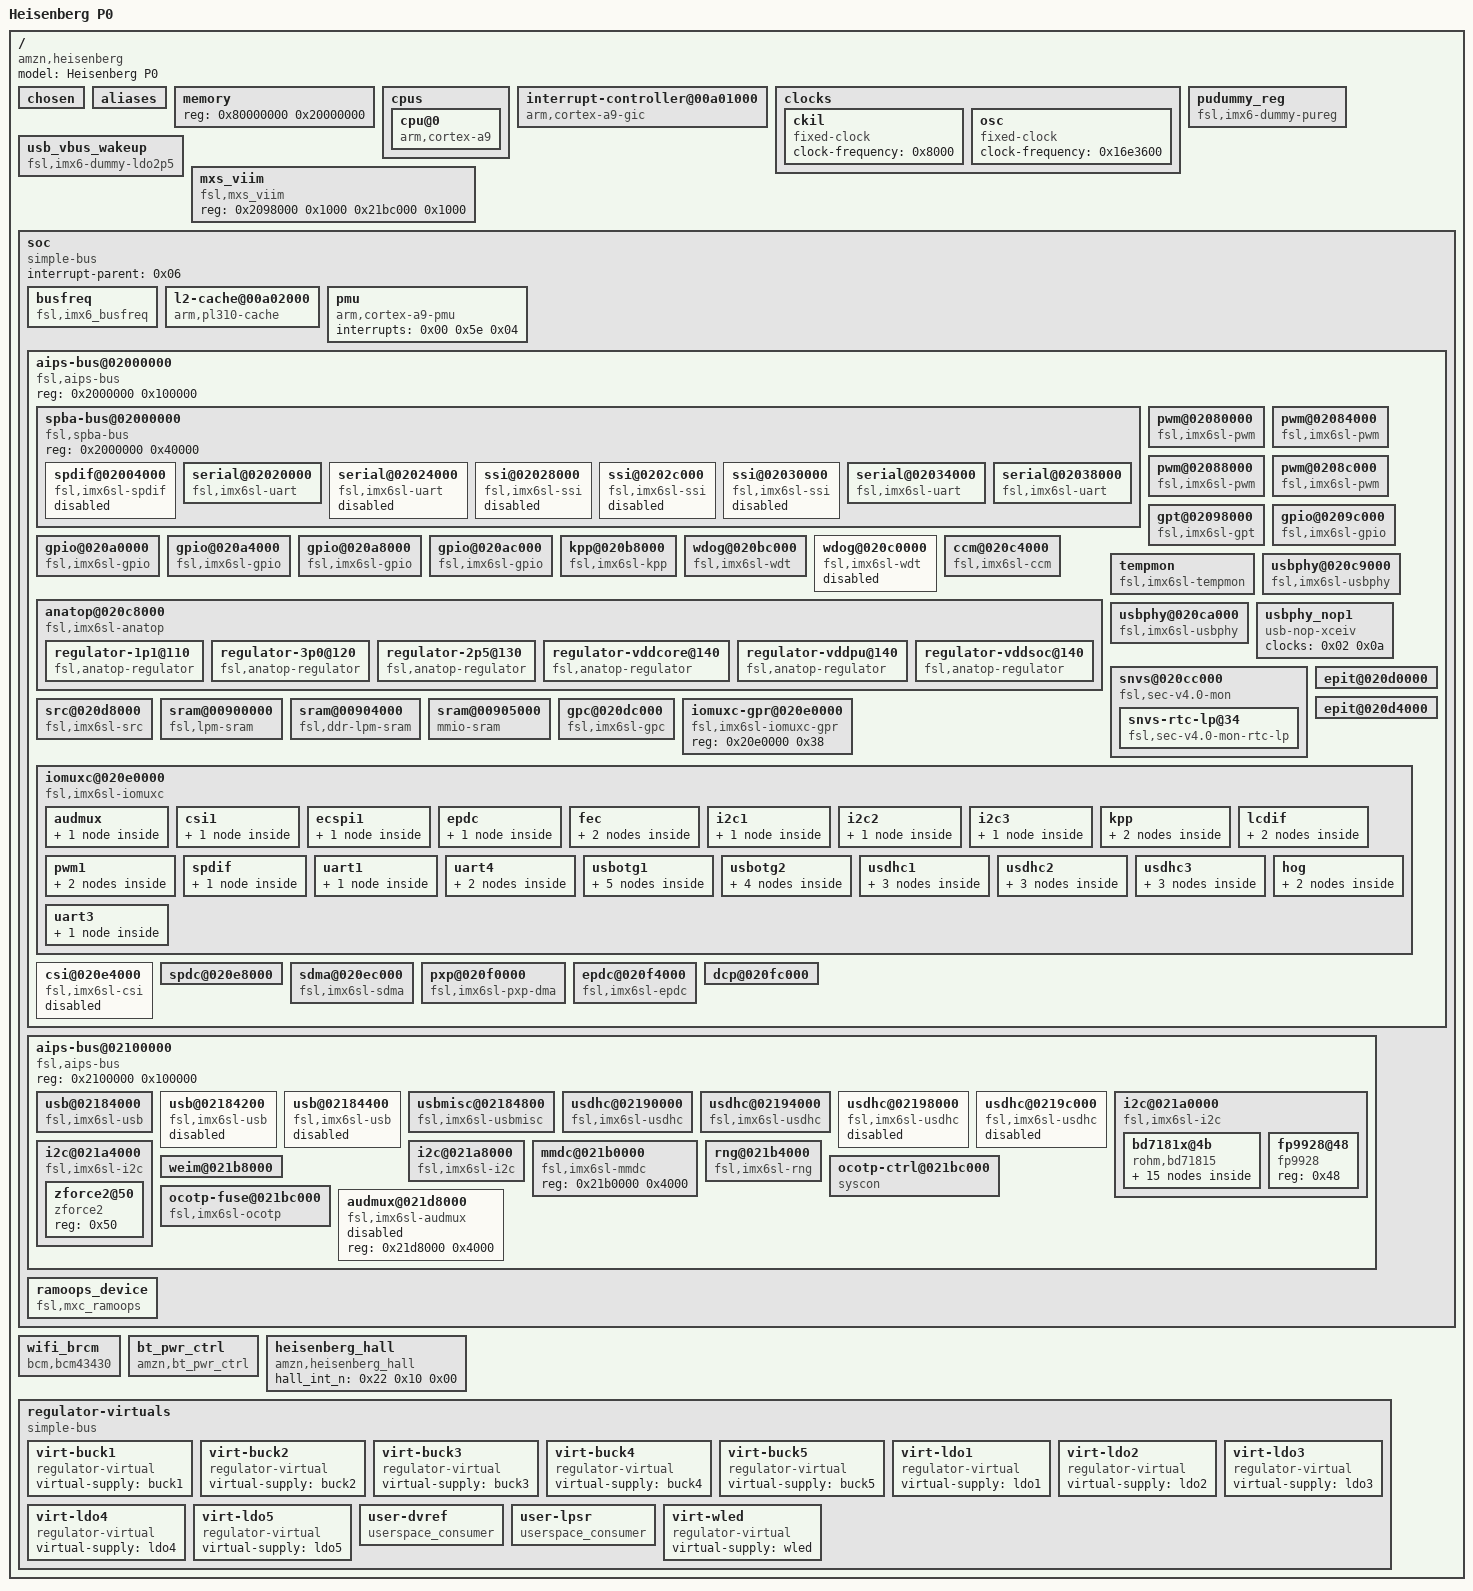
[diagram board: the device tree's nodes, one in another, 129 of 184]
/dts-v1/;

/ {
	#address-cells = <0x01>;
	#size-cells = <0x01>;
	model = "Heisenberg P0";
	compatible = "amzn,heisenberg\0fsl,imx6sl";

	chosen {
	};

	aliases {
		csi0 = "/soc/aips-bus@02000000/csi@020e4000";
		mmc1 = "/soc/aips-bus@02100000/usdhc@02190000";
		mmc0 = "/soc/aips-bus@02100000/usdhc@02194000";
		mmc2 = "/soc/aips-bus@02100000/usdhc@02198000";
		mmc3 = "/soc/aips-bus@02100000/usdhc@0219c000";
		serial0 = "/soc/aips-bus@02000000/spba-bus@02000000/serial@02020000";
		serial1 = "/soc/aips-bus@02000000/spba-bus@02000000/serial@02024000";
		serial2 = "/soc/aips-bus@02000000/spba-bus@02000000/serial@02034000";
		serial3 = "/soc/aips-bus@02000000/spba-bus@02000000/serial@02038000";
		gpio0 = "/soc/aips-bus@02000000/gpio@0209c000";
		gpio1 = "/soc/aips-bus@02000000/gpio@020a0000";
		gpio2 = "/soc/aips-bus@02000000/gpio@020a4000";
		gpio3 = "/soc/aips-bus@02000000/gpio@020a8000";
		gpio4 = "/soc/aips-bus@02000000/gpio@020ac000";
		usbphy0 = "/soc/aips-bus@02000000/usbphy@020c9000";
		usbphy1 = "/soc/aips-bus@02000000/usbphy@020ca000";
	};

	memory {
		device_type = "memory";
		reg = <0x80000000 0x20000000>;
	};

	cpus {
		#address-cells = <0x01>;
		#size-cells = <0x00>;

		cpu@0 {
			compatible = "arm,cortex-a9";
			device_type = "cpu";
			reg = <0x00>;
			next-level-cache = <0x01>;
			operating-points = <0xf32a0 0x137478 0x60ae0 0xee098>;
			fsl,soc-operating-points = <0xf32a0 0x12b128 0x60ae0 0x11edd8>;
			clock-latency = <0xee6c>;
			clocks = <0x02 0x5f 0x02 0x14 0x02 0x1d 0x02 0x1e 0x02 0x03>;
			clock-names = "arm\0pll2_pfd2_396m\0step\0pll1_sw\0pll1_sys";
			arm-supply = <0x03>;
			pu-supply = <0x04>;
			soc-supply = <0x05>;
		};
	};

	interrupt-controller@00a01000 {
		compatible = "arm,cortex-a9-gic";
		#interrupt-cells = <0x03>;
		#address-cells = <0x01>;
		#size-cells = <0x01>;
		interrupt-controller;
		reg = <0xa01000 0x1000 0xa00100 0x100>;
		linux,phandle = <0x06>;
		phandle = <0x06>;
	};

	clocks {
		#address-cells = <0x01>;
		#size-cells = <0x00>;

		ckil {
			compatible = "fixed-clock";
			clock-frequency = <0x8000>;
		};

		osc {
			compatible = "fixed-clock";
			clock-frequency = <0x16e3600>;
		};
	};

	pudummy_reg {
		compatible = "fsl,imx6-dummy-pureg";
		linux,phandle = <0x04>;
		phandle = <0x04>;
	};

	usb_vbus_wakeup {
		compatible = "fsl,imx6-dummy-ldo2p5";
		linux,phandle = <0x1a>;
		phandle = <0x1a>;
	};

	mxs_viim {
		compatible = "fsl,mxs_viim";
		reg = <0x2098000 0x1000 0x21bc000 0x1000>;
	};

	soc {
		#address-cells = <0x01>;
		#size-cells = <0x01>;
		compatible = "simple-bus";
		interrupt-parent = <0x06>;
		ranges;

		busfreq {
			compatible = "fsl,imx6_busfreq";
			clocks = <0x02 0x04 0x02 0x14 0x02 0x19 0x02 0x5f 0x02 0x05 0x02 0x3a 0x02 0x22 0x02 0x3d 0x02 0x24 0x02 0x02 0x02 0x03 0x02 0x3b 0x02 0x5d 0x02 0x74 0x02 0x1e 0x02 0x21 0x02 0x23 0x02 0x3e 0x02 0x1d>;
			clock-names = "pll2_bus\0pll2_pfd2_396m\0pll2_198m\0arm\0pll3_usb_otg\0periph\0periph_pre\0periph_clk2\0periph_clk2_sel\0osc\0pll1_sys\0periph2\0ahb\0ocram\0pll1_sw\0periph2_pre\0periph2_clk2_sel\0periph2_clk2\0step";
			fsl,max_ddr_freq = <0x17d78400>;
		};

		l2-cache@00a02000 {
			compatible = "arm,pl310-cache";
			reg = <0xa02000 0x1000>;
			interrupts = <0x00 0x5c 0x04>;
			cache-unified;
			cache-level = <0x02>;
			arm,tag-latency = <0x04 0x02 0x03>;
			arm,data-latency = <0x04 0x02 0x03>;
			linux,phandle = <0x01>;
			phandle = <0x01>;
		};

		pmu {
			compatible = "arm,cortex-a9-pmu";
			interrupts = <0x00 0x5e 0x04>;
		};

		aips-bus@02000000 {
			compatible = "fsl,aips-bus\0simple-bus";
			#address-cells = <0x01>;
			#size-cells = <0x01>;
			reg = <0x2000000 0x100000>;
			ranges;

			spba-bus@02000000 {
				compatible = "fsl,spba-bus\0simple-bus";
				#address-cells = <0x01>;
				#size-cells = <0x01>;
				reg = <0x2000000 0x40000>;
				ranges;

				spdif@02004000 {
					compatible = "fsl,imx6sl-spdif\0fsl,imx35-spdif";
					reg = <0x2004000 0x4000>;
					interrupts = <0x00 0x34 0x04>;
					dmas = <0x07 0x0e 0x12 0x00 0x07 0x0f 0x12 0x00>;
					dma-names = "rx\0tx";
					clocks = <0x02 0x7a 0x02 0x02 0x02 0x7a 0x02 0x00 0x02 0x00 0x02 0x00 0x02 0x3f 0x02 0x00 0x02 0x00 0x02 0x88>;
					clock-names = "core\0rxtx0\0rxtx1\0rxtx2\0rxtx3\0rxtx4\0rxtx5\0rxtx6\0rxtx7\0dma";
					status = "disabled";
				};

				serial@02020000 {
					compatible = "fsl,imx6sl-uart\0fsl,imx21-uart";
					reg = <0x2020000 0x4000>;
					interrupts = <0x00 0x1a 0x04>;
					clocks = <0x02 0x7e 0x02 0x7f>;
					clock-names = "ipg\0per";
					dmas = <0x07 0x19 0x04 0x00 0x07 0x1a 0x04 0x00>;
					dma-names = "rx\0tx";
					status = "okay";
					pinctrl-names = "default";
					pinctrl-0 = <0x08>;
				};

				serial@02024000 {
					compatible = "fsl,imx6sl-uart\0fsl,imx21-uart";
					reg = <0x2024000 0x4000>;
					interrupts = <0x00 0x1b 0x04>;
					clocks = <0x02 0x7e 0x02 0x7f>;
					clock-names = "ipg\0per";
					dmas = <0x07 0x1b 0x04 0x00 0x07 0x1c 0x04 0x00>;
					dma-names = "rx\0tx";
					status = "disabled";
				};

				ssi@02028000 {
					compatible = "fsl,imx6sl-ssi\0fsl,imx21-ssi";
					reg = <0x2028000 0x4000>;
					interrupts = <0x00 0x2e 0x04>;
					clocks = <0x02 0x7b 0x02 0x7b>;
					clock-names = "ipg\0baud";
					dmas = <0x07 0x25 0x01 0x00 0x07 0x26 0x01 0x00>;
					dma-names = "rx\0tx";
					status = "disabled";
				};

				ssi@0202c000 {
					compatible = "fsl,imx6sl-ssi\0fsl,imx21-ssi";
					reg = <0x202c000 0x4000>;
					interrupts = <0x00 0x2f 0x04>;
					clocks = <0x02 0x7c 0x02 0x7c>;
					clock-names = "ipg\0baud";
					dmas = <0x07 0x29 0x01 0x00 0x07 0x2a 0x01 0x00>;
					dma-names = "rx\0tx";
					status = "disabled";
				};

				ssi@02030000 {
					compatible = "fsl,imx6sl-ssi\0fsl,imx21-ssi";
					reg = <0x2030000 0x4000>;
					interrupts = <0x00 0x30 0x04>;
					clocks = <0x02 0x7d 0x02 0x7d>;
					clock-names = "ipg\0baud";
					dmas = <0x07 0x2d 0x01 0x00 0x07 0x2e 0x01 0x00>;
					dma-names = "rx\0tx";
					status = "disabled";
				};

				serial@02034000 {
					compatible = "fsl,imx6sl-uart\0fsl,imx21-uart";
					reg = <0x2034000 0x4000>;
					interrupts = <0x00 0x1c 0x04>;
					clocks = <0x02 0x7e 0x02 0x7f>;
					clock-names = "ipg\0per";
					dmas = <0x07 0x1d 0x04 0x00 0x07 0x1e 0x04 0x00>;
					dma-names = "rx\0tx";
					status = "okay";
					pinctrl-names = "default";
					pinctrl-0 = <0x09>;
					fsl,uart-has-rtscts;
				};

				serial@02038000 {
					compatible = "fsl,imx6sl-uart\0fsl,imx21-uart";
					reg = <0x2038000 0x4000>;
					interrupts = <0x00 0x1d 0x04>;
					clocks = <0x02 0x7e 0x02 0x7f>;
					clock-names = "ipg\0per";
					dmas = <0x07 0x1f 0x04 0x00 0x07 0x20 0x04 0x00>;
					dma-names = "rx\0tx";
					status = "okay";
					pinctrl-names = "default";
					pinctrl-0 = <0x0a>;
				};
			};

			pwm@02080000 {
				#pwm-cells = <0x02>;
				compatible = "fsl,imx6sl-pwm\0fsl,imx27-pwm";
				reg = <0x2080000 0x4000>;
				interrupts = <0x00 0x53 0x04>;
				clocks = <0x02 0x75 0x02 0x75>;
				clock-names = "ipg\0per";
			};

			pwm@02084000 {
				#pwm-cells = <0x02>;
				compatible = "fsl,imx6sl-pwm\0fsl,imx27-pwm";
				reg = <0x2084000 0x4000>;
				interrupts = <0x00 0x54 0x04>;
				clocks = <0x02 0x76 0x02 0x76>;
				clock-names = "ipg\0per";
			};

			pwm@02088000 {
				#pwm-cells = <0x02>;
				compatible = "fsl,imx6sl-pwm\0fsl,imx27-pwm";
				reg = <0x2088000 0x4000>;
				interrupts = <0x00 0x55 0x04>;
				clocks = <0x02 0x77 0x02 0x77>;
				clock-names = "ipg\0per";
			};

			pwm@0208c000 {
				#pwm-cells = <0x02>;
				compatible = "fsl,imx6sl-pwm\0fsl,imx27-pwm";
				reg = <0x208c000 0x4000>;
				interrupts = <0x00 0x56 0x04>;
				clocks = <0x02 0x78 0x02 0x78>;
				clock-names = "ipg\0per";
			};

			gpt@02098000 {
				compatible = "fsl,imx6sl-gpt";
				reg = <0x2098000 0x4000>;
				interrupts = <0x00 0x37 0x04>;
				clocks = <0x02 0x67 0x02 0x68>;
				clock-names = "ipg\0per";
			};

			gpio@0209c000 {
				compatible = "fsl,imx6sl-gpio\0fsl,imx35-gpio";
				reg = <0x209c000 0x4000>;
				interrupts = <0x00 0x42 0x04 0x00 0x43 0x04>;
				gpio-controller;
				#gpio-cells = <0x02>;
				interrupt-controller;
				#interrupt-cells = <0x02>;
			};

			gpio@020a0000 {
				compatible = "fsl,imx6sl-gpio\0fsl,imx35-gpio";
				reg = <0x20a0000 0x4000>;
				interrupts = <0x00 0x44 0x04 0x00 0x45 0x04>;
				gpio-controller;
				#gpio-cells = <0x02>;
				interrupt-controller;
				#interrupt-cells = <0x02>;
				linux,phandle = <0x25>;
				phandle = <0x25>;
			};

			gpio@020a4000 {
				compatible = "fsl,imx6sl-gpio\0fsl,imx35-gpio";
				reg = <0x20a4000 0x4000>;
				interrupts = <0x00 0x46 0x04 0x00 0x47 0x04>;
				gpio-controller;
				#gpio-cells = <0x02>;
				interrupt-controller;
				#interrupt-cells = <0x02>;
				linux,phandle = <0x26>;
				phandle = <0x26>;
			};

			gpio@020a8000 {
				compatible = "fsl,imx6sl-gpio\0fsl,imx35-gpio";
				reg = <0x20a8000 0x4000>;
				interrupts = <0x00 0x48 0x04 0x00 0x49 0x04>;
				gpio-controller;
				#gpio-cells = <0x02>;
				interrupt-controller;
				#interrupt-cells = <0x02>;
				linux,phandle = <0x22>;
				phandle = <0x22>;
			};

			gpio@020ac000 {
				compatible = "fsl,imx6sl-gpio\0fsl,imx35-gpio";
				reg = <0x20ac000 0x4000>;
				interrupts = <0x00 0x4a 0x04 0x00 0x4b 0x04>;
				gpio-controller;
				#gpio-cells = <0x02>;
				interrupt-controller;
				#interrupt-cells = <0x02>;
				linux,phandle = <0x27>;
				phandle = <0x27>;
			};

			kpp@020b8000 {
				compatible = "fsl,imx6sl-kpp\0fsl,imx21-kpp";
				reg = <0x20b8000 0x4000>;
				interrupts = <0x00 0x52 0x04>;
				clocks = <0x02 0x00>;
				pinctrl-names = "default";
				pinctrl-0 = <0x0b>;
				status = "okay";
			};

			wdog@020bc000 {
				compatible = "fsl,imx6sl-wdt\0fsl,imx21-wdt";
				reg = <0x20bc000 0x4000>;
				interrupts = <0x00 0x50 0x04>;
				clocks = <0x02 0x00>;
			};

			wdog@020c0000 {
				compatible = "fsl,imx6sl-wdt\0fsl,imx21-wdt";
				reg = <0x20c0000 0x4000>;
				interrupts = <0x00 0x51 0x04>;
				clocks = <0x02 0x00>;
				status = "disabled";
			};

			ccm@020c4000 {
				compatible = "fsl,imx6sl-ccm";
				reg = <0x20c4000 0x4000>;
				interrupts = <0x00 0x57 0x04 0x00 0x58 0x04>;
				#clock-cells = <0x01>;
				linux,phandle = <0x02>;
				phandle = <0x02>;
			};

			anatop@020c8000 {
				compatible = "fsl,imx6sl-anatop\0fsl,imx6q-anatop\0syscon\0simple-bus";
				reg = <0x20c8000 0x1000>;
				interrupts = <0x00 0x31 0x04 0x00 0x36 0x04 0x00 0x7f 0x04>;
				linux,phandle = <0x0c>;
				phandle = <0x0c>;

				regulator-1p1@110 {
					compatible = "fsl,anatop-regulator";
					regulator-name = "vdd1p1";
					regulator-min-microvolt = "\0\f5";
					regulator-max-microvolt = <0x14fb18>;
					regulator-always-on;
					anatop-reg-offset = <0x110>;
					anatop-vol-bit-shift = <0x08>;
					anatop-vol-bit-width = <0x05>;
					anatop-min-bit-val = <0x04>;
					anatop-min-voltage = "\0\f5";
					anatop-max-voltage = <0x14fb18>;
					anatop-enable-bit = <0x00>;
				};

				regulator-3p0@120 {
					compatible = "fsl,anatop-regulator";
					regulator-name = "vdd3p0";
					regulator-min-microvolt = <0x280de8>;
					regulator-max-microvolt = <0x33e140>;
					anatop-reg-offset = <0x120>;
					anatop-vol-bit-shift = <0x08>;
					anatop-vol-bit-width = <0x05>;
					anatop-min-bit-val = <0x00>;
					anatop-min-voltage = <0x280de8>;
					anatop-max-voltage = <0x33e140>;
					anatop-enable-bit = <0x00>;
					linux,phandle = <0x0e>;
					phandle = <0x0e>;
				};

				regulator-2p5@130 {
					compatible = "fsl,anatop-regulator";
					regulator-name = "vdd2p5";
					regulator-min-microvolt = <0x200b20>;
					regulator-max-microvolt = <0x2b7cd0>;
					regulator-always-on;
					anatop-reg-offset = <0x130>;
					anatop-vol-bit-shift = <0x08>;
					anatop-vol-bit-width = <0x05>;
					anatop-min-bit-val = <0x00>;
					anatop-min-voltage = <0x200b20>;
					anatop-max-voltage = <0x2b7cd0>;
					anatop-enable-bit = <0x00>;
				};

				regulator-vddcore@140 {
					compatible = "fsl,anatop-regulator";
					regulator-name = "cpu";
					regulator-min-microvolt = <0xb1008>;
					regulator-max-microvolt = <0x162010>;
					anatop-reg-offset = <0x140>;
					anatop-vol-bit-shift = <0x00>;
					anatop-vol-bit-width = <0x05>;
					anatop-delay-reg-offset = <0x170>;
					anatop-delay-bit-shift = <0x18>;
					anatop-delay-bit-width = <0x02>;
					anatop-min-bit-val = <0x01>;
					anatop-min-voltage = <0xb1008>;
					anatop-max-voltage = <0x162010>;
				};

				regulator-vddpu@140 {
					compatible = "fsl,anatop-regulator";
					regulator-name = "vddpu";
					regulator-min-microvolt = <0xb1008>;
					regulator-max-microvolt = <0x162010>;
					anatop-reg-offset = <0x140>;
					anatop-vol-bit-shift = <0x09>;
					anatop-vol-bit-width = <0x05>;
					anatop-delay-reg-offset = <0x170>;
					anatop-delay-bit-shift = <0x1a>;
					anatop-delay-bit-width = <0x02>;
					anatop-min-bit-val = <0x01>;
					anatop-min-voltage = <0xb1008>;
					anatop-max-voltage = <0x162010>;
					linux,phandle = <0x0f>;
					phandle = <0x0f>;
				};

				regulator-vddsoc@140 {
					compatible = "fsl,anatop-regulator";
					regulator-name = "vddsoc";
					regulator-min-microvolt = <0xb1008>;
					regulator-max-microvolt = <0x162010>;
					anatop-reg-offset = <0x140>;
					anatop-vol-bit-shift = <0x12>;
					anatop-vol-bit-width = <0x05>;
					anatop-delay-reg-offset = <0x170>;
					anatop-delay-bit-shift = <0x1c>;
					anatop-delay-bit-width = <0x02>;
					anatop-min-bit-val = <0x01>;
					anatop-min-voltage = <0xb1008>;
					anatop-max-voltage = <0x162010>;
				};
			};

			tempmon {
				compatible = "fsl,imx6sl-tempmon\0fsl,imx6q-tempmon";
				interrupts = <0x00 0x31 0x04>;
				fsl,tempmon = <0x0c>;
				fsl,tempmon-data = <0x0d>;
				clocks = <0x02 0x05>;
			};

			usbphy@020c9000 {
				compatible = "fsl,imx6sl-usbphy\0fsl,imx23-usbphy";
				reg = <0x20c9000 0x1000>;
				interrupts = <0x00 0x2c 0x04>;
				clocks = <0x02 0x0a>;
				phy-3p0-supply = <0x0e>;
				fsl,anatop = <0x0c>;
				linux,phandle = <0x14>;
				phandle = <0x14>;
			};

			usbphy@020ca000 {
				compatible = "fsl,imx6sl-usbphy\0fsl,imx23-usbphy";
				reg = <0x20ca000 0x1000>;
				interrupts = <0x00 0x2d 0x04>;
				clocks = <0x02 0x0b>;
				phy-3p0-supply = <0x0e>;
				fsl,anatop = <0x0c>;
				linux,phandle = <0x18>;
				phandle = <0x18>;
			};

			usbphy_nop1 {
				compatible = "usb-nop-xceiv";
				clocks = <0x02 0x0a>;
				clock-names = "main_clk";
				linux,phandle = <0x19>;
				phandle = <0x19>;
			};

			snvs@020cc000 {
				compatible = "fsl,sec-v4.0-mon\0simple-bus";
				#address-cells = <0x01>;
				#size-cells = <0x01>;
				ranges = <0x00 0x20cc000 0x4000>;

				snvs-rtc-lp@34 {
					compatible = "fsl,sec-v4.0-mon-rtc-lp";
					reg = <0x34 0x58>;
					interrupts = <0x00 0x13 0x04 0x00 0x14 0x04>;
				};
			};

			epit@020d0000 {
				reg = <0x20d0000 0x4000>;
				interrupts = <0x00 0x38 0x04>;
			};

			epit@020d4000 {
				reg = <0x20d4000 0x4000>;
				interrupts = <0x00 0x39 0x04>;
			};

			src@020d8000 {
				compatible = "fsl,imx6sl-src\0fsl,imx51-src";
				reg = <0x20d8000 0x4000>;
				interrupts = <0x00 0x5b 0x04 0x00 0x60 0x04>;
				#reset-cells = <0x01>;
			};

			sram@00900000 {
				compatible = "fsl,lpm-sram";
				reg = <0x900000 0x4000>;
				clocks = <0x02 0x74>;
				clock-names = "ocram";
			};

			sram@00904000 {
				compatible = "fsl,ddr-lpm-sram";
				reg = <0x904000 0x1000>;
				clocks = <0x02 0x74>;
				clock-names = "ocram";
			};

			sram@00905000 {
				compatible = "mmio-sram";
				reg = <0x905000 0x1b000>;
				clocks = <0x02 0x74>;
				clock-names = "ocram";
				linux,phandle = <0x12>;
				phandle = <0x12>;
			};

			gpc@020dc000 {
				compatible = "fsl,imx6sl-gpc\0fsl,imx6q-gpc";
				reg = <0x20dc000 0x4000>;
				interrupts = <0x00 0x59 0x04>;
				clocks = <0x02 0x50 0x02 0x69 0x02 0x3f 0x02 0x71 0x02 0x72 0x02 0x70 0x02 0x73 0x02 0x6f>;
				clock-names = "gpu2d_podf\0gpu2d_ovg\0ipg\0lcd_axi\0lcd_pix\0epdc_axi\0epdc_pix\0pxp_axi";
				pu-supply = <0x0f>;
			};

			iomuxc-gpr@020e0000 {
				compatible = "fsl,imx6sl-iomuxc-gpr\0syscon";
				reg = <0x20e0000 0x38>;
			};

			iomuxc@020e0000 {
				compatible = "fsl,imx6sl-iomuxc";
				reg = <0x20e0000 0x4000>;
				pinctrl-names = "default\0sleep";
				pinctrl-0 = <0x10>;
				pinctrl-1 = <0x11>;

				audmux {

					audmux-1 {
						fsl,pins = <0x54 0x2ac 0x00 0x00 0x00 0x4130b0 0x5c 0x2b4 0x00 0x00 0x00 0x4130b0 0x60 0x2b8 0x00 0x00 0x00 0x4110b0 0x64 0x2bc 0x00 0x00 0x00 0x4130b0 0x4c 0x2a4 0x00 0x00 0x00 0x4130b0>;
					};
				};

				csi1 {

					csigrp-0 {
						fsl,pins = <0xd8 0x3c8 0x00 0x03 0x00 0x110b0 0xd0 0x3c0 0x674 0x03 0x01 0x110b0 0xdc 0x3cc 0x678 0x03 0x01 0x110b0 0xd4 0x3c4 0x670 0x03 0x01 0x110b0 0x114 0x404 0x654 0x03 0x00 0x110b0 0x110 0x400 0x650 0x03 0x00 0x110b0 0xc4 0x3b4 0x64c 0x03 0x00 0x110b0 0xc0 0x3b0 0x648 0x03 0x00 0x110b0 0xbc 0x3ac 0x644 0x03 0x00 0x110b0 0xb8 0x3a8 0x640 0x03 0x00 0x110b0 0xb4 0x3a4 0x63c 0x03 0x00 0x110b0 0xb0 0x3a0 0x638 0x03 0x00 0x110b0 0x94 0x384 0x634 0x03 0x00 0x110b0 0x90 0x380 0x630 0x03 0x00 0x110b0 0x11c 0x40c 0x00 0x05 0x00 0x80000000 0x118 0x408 0x00 0x05 0x00 0x80000000>;
					};
				};

				ecspi1 {

					ecspi1grp-1 {
						fsl,pins = <0x68 0x358 0x684 0x00 0x00 0x100b1 0x6c 0x35c 0x688 0x00 0x00 0x100b1 0x70 0x360 0x67c 0x00 0x00 0x100b1>;
					};
				};

				epdc {

					epdcgrp-0 {
						fsl,pins = <0x90 0x380 0x00 0x00 0x00 0x4110a1 0x94 0x384 0x00 0x00 0x00 0x4110a1 0xb0 0x3a0 0x00 0x00 0x00 0x4110a1 0xb4 0x3a4 0x00 0x00 0x00 0x4110a1 0xb8 0x3a8 0x00 0x00 0x00 0x4110a1 0xbc 0x3ac 0x00 0x00 0x00 0x4110a1 0xc0 0x3b0 0x00 0x00 0x00 0x4110a1 0xc4 0x3b4 0x00 0x00 0x00 0x4110a1 0xd0 0x3c0 0x00 0x00 0x00 0x4110a0 0xdc 0x3cc 0x00 0x00 0x00 0x4110a0 0xd4 0x3c4 0x00 0x00 0x00 0x4110a0 0x110 0x400 0x00 0x00 0x00 0x4110a9 0x118 0x408 0x00 0x00 0x00 0x4110a9 0x114 0x404 0x00 0x00 0x00 0x4110a1 0x100 0x3f0 0x00 0x00 0x00 0x4110a0>;
						linux,phandle = <0x13>;
						phandle = <0x13>;
					};
				};

				fec {

					fecgrp-1 {
						fsl,pins = <0x12c 0x41c 0x00 0x00 0x00 0x1b0b0 0x130 0x420 0x6f4 0x00 0x01 0x1b0b0 0x128 0x418 0x704 0x00 0x01 0x1b0b0 0x13c 0x42c 0x6f8 0x00 0x00 0x1b0b0 0x140 0x430 0x6fc 0x00 0x01 0x1b0b0 0x148 0x438 0x00 0x00 0x00 0x1b0b0 0x14c 0x43c 0x00 0x00 0x00 0x1b0b0 0x150 0x440 0x00 0x00 0x00 0x1b0b0 0x134 0x424 0x00 0x00 0x00 0x4001b0a8>;
					};

					fecgrp-1-sleep {
						fsl,pins = <0x12c 0x41c 0x00 0x05 0x00 0x3080 0x128 0x418 0x00 0x05 0x00 0x3080 0x13c 0x42c 0x00 0x05 0x00 0x3080 0x140 0x430 0x00 0x05 0x00 0x3080 0x148 0x438 0x00 0x05 0x00 0x3080 0x14c 0x43c 0x00 0x05 0x00 0x3080 0x150 0x440 0x00 0x05 0x00 0x3080 0x134 0x424 0x00 0x05 0x00 0x3080>;
					};
				};

				i2c1 {

					i2c1grp-1 {
						fsl,pins = <0x15c 0x44c 0x71c 0x00 0x02 0x404108b1 0x160 0x450 0x720 0x00 0x02 0x404108b1>;
						linux,phandle = <0x21>;
						phandle = <0x21>;
					};
				};

				i2c2 {

					i2c2grp-1 {
						fsl,pins = <0x164 0x454 0x724 0x00 0x01 0x400108a8 0x168 0x458 0x728 0x00 0x01 0x400108a8>;
						linux,phandle = <0x23>;
						phandle = <0x23>;
					};
				};

				i2c3 {

					i2c3grp-1 {
						fsl,pins = <0x108 0x3f8 0x72c 0x01 0x01 0x400108a8 0x10c 0x3fc 0x730 0x01 0x01 0x400108a8>;
						linux,phandle = <0x24>;
						phandle = <0x24>;
					};
				};

				kpp {

					kpp_grp_1 {
						fsl,pins = <0x1a0 0x4a8 0x00 0x05 0x00 0x100b0 0x1a4 0x4ac 0x00 0x05 0x00 0x108b0 0x16c 0x474 0x00 0x05 0x00 0x100b0>;
						linux,phandle = <0x0b>;
						phandle = <0x0b>;
					};

					kpp_grp_1_sleep {
						fsl,pins = <0x18c 0x494 0x00 0x05 0x00 0x3080 0x190 0x498 0x00 0x05 0x00 0x3080 0x194 0x49c 0x00 0x05 0x00 0x3080 0x16c 0x474 0x00 0x05 0x00 0x3080 0x170 0x478 0x00 0x05 0x00 0x3080 0x174 0x47c 0x00 0x05 0x00 0x3080>;
					};
				};

				lcdif {

					lcdifdatgrp-0 {
						fsl,pins = <0x1b0 0x4b8 0x778 0x00 0x01 0x1b0b0 0x1b4 0x4bc 0x77c 0x00 0x01 0x1b0b0 0x1e0 0x4e8 0x780 0x00 0x01 0x1b0b0 0x1f4 0x4fc 0x784 0x00 0x01 0x1b0b0 0x1f8 0x500 0x788 0x00 0x01 0x1b0b0 0x1fc 0x504 0x78c 0x00 0x01 0x1b0b0 0x200 0x508 0x790 0x00 0x01 0x1b0b0 0x204 0x50c 0x794 0x00 0x01 0x1b0b0 0x208 0x510 0x798 0x00 0x01 0x1b0b0 0x20c 0x514 0x79c 0x00 0x01 0x1b0b0 0x1b8 0x4c0 0x7a0 0x00 0x01 0x1b0b0 0x1bc 0x4c4 0x7a4 0x00 0x01 0x1b0b0 0x1c0 0x4c8 0x7a8 0x00 0x01 0x1b0b0 0x1c4 0x4cc 0x7ac 0x00 0x01 0x1b0b0 0x1c8 0x4d0 0x7b0 0x00 0x01 0x1b0b0 0x1cc 0x4d4 0x7b4 0x00 0x01 0x1b0b0 0x1d0 0x4d8 0x7b8 0x00 0x01 0x1b0b0 0x1d4 0x4dc 0x7bc 0x00 0x01 0x1b0b0 0x1d8 0x4e0 0x7c0 0x00 0x01 0x1b0b0 0x1dc 0x4e4 0x7c4 0x00 0x01 0x1b0b0 0x1e4 0x4ec 0x7c8 0x00 0x01 0x1b0b0 0x1e8 0x4f0 0x7cc 0x00 0x01 0x1b0b0 0x1ec 0x4f4 0x7d0 0x00 0x01 0x1b0b0 0x1f0 0x4f8 0x7d4 0x00 0x01 0x1b0b0>;
					};

					lcdifctrlgrp-0 {
						fsl,pins = <0x1ac 0x4b4 0x00 0x00 0x00 0x1b0b0 0x210 0x518 0x00 0x00 0x00 0x1b0b0 0x214 0x51c 0x774 0x00 0x00 0x1b0b0 0x21c 0x524 0x00 0x00 0x00 0x1b0b0>;
					};
				};

				pwm1 {

					pwm1grp-0 {
						fsl,pins = <0x220 0x528 0x00 0x00 0x00 0x110b0>;
					};

					pwm1grp-0-sleep {
						fsl,pins = <0x220 0x528 0x00 0x05 0x00 0x3080>;
					};
				};

				spdif {

					spdifgrp-1 {
						fsl,pins = <0x26c 0x574 0x00 0x04 0x00 0x80000000>;
					};
				};

				uart1 {

					uart1grp-1 {
						fsl,pins = <0x298 0x5a0 0x7fc 0x00 0x00 0x41b0b1 0x29c 0x5a4 0x00 0x00 0x00 0x41b0b1>;
						linux,phandle = <0x08>;
						phandle = <0x08>;
					};
				};

				uart4 {

					uart4grp-1 {
						fsl,pins = <0x244 0x54c 0x814 0x04 0x04 0x1b0b1 0x248 0x550 0x00 0x04 0x00 0x1b0b1>;
						linux,phandle = <0x0a>;
						phandle = <0x0a>;
					};

					uart4dtegrp-1 {
						fsl,pins = <0x248 0x550 0x814 0x04 0x05 0x1b0b1 0x244 0x54c 0x00 0x04 0x00 0x1b0b1 0x24c 0x554 0x00 0x04 0x00 0x1b0b1 0x250 0x558 0x810 0x04 0x05 0x1b0b1>;
					};
				};

				usbotg1 {

					usbotg1grp-1 {
						fsl,pins = <0xe0 0x3d0 0x5dc 0x04 0x00 0x17059>;
						linux,phandle = <0x17>;
						phandle = <0x17>;
					};

					usbotg1grp-2 {
						fsl,pins = <0x13c 0x42c 0x5dc 0x02 0x01 0x17059>;
					};

					usbotg1grp-3 {
						fsl,pins = <0x1b4 0x4bc 0x5dc 0x02 0x02 0x17059>;
					};

					usbotg1grp-4 {
						fsl,pins = <0x228 0x530 0x5dc 0x03 0x03 0x17059>;
					};

					usbotg1grp-5 {
						fsl,pins = <0x288 0x590 0x5dc 0x04 0x04 0x17059>;
					};
				};

				usbotg2 {

					usbotg2grp-1 {
						fsl,pins = <0x70 0x360 0x820 0x06 0x00 0x17059>;
					};

					usbotg2grp-2 {
						fsl,pins = <0x80 0x370 0x820 0x06 0x01 0x17059>;
					};

					usbotg2grp-3 {
						fsl,pins = <0x1a0 0x4a8 0x820 0x06 0x02 0x17059>;
					};

					usbotg2grp-4 {
						fsl,pins = <0x290 0x598 0x820 0x06 0x03 0x17059>;
					};
				};

				usdhc1 {

					usdhc1grp-1 {
						fsl,pins = <0x230 0x538 0x00 0x00 0x00 0x407059 0x22c 0x534 0x00 0x00 0x00 0x4000d9 0x234 0x53c 0x00 0x00 0x00 0x407059 0x238 0x540 0x00 0x00 0x00 0x407059 0x23c 0x544 0x00 0x00 0x00 0x407059 0x240 0x548 0x00 0x00 0x00 0x407059>;
						linux,phandle = <0x1b>;
						phandle = <0x1b>;
					};

					usdhc1grp-1-100mhz {
						fsl,pins = <0x230 0x538 0x00 0x00 0x00 0x4070a9 0x22c 0x534 0x00 0x00 0x00 0x4000f9 0x234 0x53c 0x00 0x00 0x00 0x4070a9 0x238 0x540 0x00 0x00 0x00 0x4070a9 0x23c 0x544 0x00 0x00 0x00 0x4070a9 0x240 0x548 0x00 0x00 0x00 0x4070a9>;
						linux,phandle = <0x1c>;
						phandle = <0x1c>;
					};

					usdhc1grp-1-200mhz {
						fsl,pins = <0x230 0x538 0x00 0x00 0x00 0x4070e9 0x22c 0x534 0x00 0x00 0x00 0x4000f9 0x234 0x53c 0x00 0x00 0x00 0x4070e9 0x238 0x540 0x00 0x00 0x00 0x4070e9 0x23c 0x544 0x00 0x00 0x00 0x4070e9 0x240 0x548 0x00 0x00 0x00 0x4070e9>;
						linux,phandle = <0x1d>;
						phandle = <0x1d>;
					};
				};

				usdhc2 {

					usdhc2grp-1 {
						fsl,pins = <0x258 0x560 0x00 0x00 0x00 0x407059 0x254 0x55c 0x00 0x00 0x00 0x400059 0x25c 0x564 0x00 0x00 0x00 0x407059 0x260 0x568 0x00 0x00 0x00 0x407059 0x264 0x56c 0x00 0x00 0x00 0x407059 0x268 0x570 0x00 0x00 0x00 0x407059 0x26c 0x574 0x00 0x00 0x00 0x407059 0x270 0x578 0x00 0x00 0x00 0x407059 0x274 0x57c 0x00 0x00 0x00 0x407059 0x278 0x580 0x00 0x00 0x00 0x407059 0x27c 0x584 0x00 0x00 0x00 0x407059>;
						linux,phandle = <0x1e>;
						phandle = <0x1e>;
					};

					usdhc2grp-1-100mhz {
						fsl,pins = <0x258 0x560 0x00 0x00 0x00 0x4070b9 0x254 0x55c 0x00 0x00 0x00 0x4000b9 0x25c 0x564 0x00 0x00 0x00 0x4070b9 0x260 0x568 0x00 0x00 0x00 0x4070b9 0x264 0x56c 0x00 0x00 0x00 0x4070b9 0x268 0x570 0x00 0x00 0x00 0x4070b9 0x26c 0x574 0x00 0x00 0x00 0x4070b9 0x270 0x578 0x00 0x00 0x00 0x4070b9 0x274 0x57c 0x00 0x00 0x00 0x4070b9 0x278 0x580 0x00 0x00 0x00 0x4070b9 0x27c 0x584 0x00 0x00 0x00 0x4070b9>;
						linux,phandle = <0x1f>;
						phandle = <0x1f>;
					};

					usdhc2grp-1-200mhz {
						fsl,pins = <0x258 0x560 0x00 0x00 0x00 0x4070f9 0x254 0x55c 0x00 0x00 0x00 0x4000f9 0x25c 0x564 0x00 0x00 0x00 0x4070f9 0x260 0x568 0x00 0x00 0x00 0x4070f9 0x264 0x56c 0x00 0x00 0x00 0x4070f9 0x268 0x570 0x00 0x00 0x00 0x4070f9 0x26c 0x574 0x00 0x00 0x00 0x4070f9 0x270 0x578 0x00 0x00 0x00 0x4070f9 0x274 0x57c 0x00 0x00 0x00 0x4070f9 0x278 0x580 0x00 0x00 0x00 0x4070f9 0x27c 0x584 0x00 0x00 0x00 0x4070f9>;
						linux,phandle = <0x20>;
						phandle = <0x20>;
					};
				};

				usdhc3 {

					usdhc3grp-1 {
						fsl,pins = <0x284 0x58c 0x00 0x00 0x00 0x17059 0x280 0x588 0x00 0x00 0x00 0x10059 0x288 0x590 0x00 0x00 0x00 0x17059 0x28c 0x594 0x00 0x00 0x00 0x17059 0x290 0x598 0x00 0x00 0x00 0x17059 0x294 0x59c 0x00 0x00 0x00 0x17059>;
					};

					usdhc3grp-1-100mhz {
						fsl,pins = <0x284 0x58c 0x00 0x00 0x00 0x170b9 0x280 0x588 0x00 0x00 0x00 0x100b9 0x288 0x590 0x00 0x00 0x00 0x170b9 0x28c 0x594 0x00 0x00 0x00 0x170b9 0x290 0x598 0x00 0x00 0x00 0x170b9 0x294 0x59c 0x00 0x00 0x00 0x170b9>;
					};

					usdhc3grp-1-200mhz {
						fsl,pins = <0x284 0x58c 0x00 0x00 0x00 0x170f9 0x280 0x588 0x00 0x00 0x00 0x100f9 0x288 0x590 0x00 0x00 0x00 0x170f9 0x28c 0x594 0x00 0x00 0x00 0x170f9 0x290 0x598 0x00 0x00 0x00 0x170f9 0x294 0x59c 0x00 0x00 0x00 0x170f9>;
					};
				};

				hog {

					hoggrp {
						fsl,pins = <0x2a0 0x5a8 0x00 0x00 0x00 0x4128b0 0x150 0x440 0x00 0x05 0x00 0x4100b0 0x24c 0x554 0x00 0x05 0x00 0x4100b0 0x250 0x558 0x00 0x05 0x00 0x4100b0 0x194 0x49c 0x00 0x05 0x00 0x4130b0 0x198 0x4a0 0x00 0x05 0x00 0x4130b0 0x1ac 0x4b4 0x00 0x05 0x00 0x4170b0 0x218 0x520 0x00 0x05 0x00 0x4000b0 0x1f4 0x4fc 0x5e4 0x04 0x01 0x4100b0 0x1f8 0x500 0x5f4 0x04 0x01 0x4100b0 0x1fc 0x504 0x5f8 0x04 0x01 0x4100b0 0x200 0x508 0x5e8 0x04 0x01 0x4100b0 0x19c 0x4a4 0x00 0x05 0x00 0x100b0 0x18c 0x494 0x00 0x05 0x00 0x100b0 0x190 0x498 0x00 0x05 0x00 0x100b0 0x17c 0x484 0x00 0x05 0x00 0x4100b0 0x130 0x420 0x00 0x05 0x00 0x4100b0 0x13c 0x42c 0x00 0x05 0x00 0x4100b0 0xe0 0x3d0 0x00 0x05 0x00 0x4130b0 0xc8 0x3b8 0x00 0x05 0x00 0x4130b0 0xcc 0x3bc 0x00 0x05 0x00 0x4130b0 0x98 0x388 0x00 0x05 0x00 0x4130b0 0x9c 0x38c 0x00 0x05 0x00 0x4130b0 0xa0 0x390 0x00 0x05 0x00 0x4130b0 0xa4 0x394 0x00 0x05 0x00 0x4130b0 0xa8 0x398 0x00 0x05 0x00 0x4130b0 0xac 0x39c 0x00 0x05 0x00 0x4130b0 0x11c 0x40c 0x00 0x05 0x00 0x4130b0 0x104 0x3f4 0x00 0x05 0x00 0x4130b0 0xd8 0x3c8 0x00 0x05 0x00 0x4130b0 0xe4 0x3d4 0x00 0x05 0x00 0x4130b0 0xe8 0x3d8 0x00 0x05 0x00 0x4130b0 0xec 0x3dc 0x00 0x05 0x00 0x4130b0 0xf0 0x3e0 0x00 0x05 0x00 0x4130b0 0xe0 0x3d0 0x00 0x05 0x00 0x4130b0 0xf4 0x3e4 0x00 0x05 0x00 0x4130b0 0xf8 0x3e8 0x00 0x05 0x00 0x4130b0 0xfc 0x3ec 0x00 0x05 0x00 0x4130b0 0x210 0x518 0x00 0x05 0x00 0x4130b0 0x214 0x51c 0x00 0x05 0x00 0x4130b0 0x21c 0x524 0x00 0x05 0x00 0x4130b0 0x1b0 0x4b8 0x00 0x05 0x00 0x4130b0 0x1b4 0x4bc 0x00 0x05 0x00 0x4130b0 0x1e0 0x4e8 0x00 0x05 0x00 0x4130b0 0x204 0x50c 0x00 0x05 0x00 0x4130b0 0x208 0x510 0x00 0x05 0x00 0x4130b0 0x20c 0x514 0x00 0x05 0x00 0x4130b0 0x1b8 0x4c0 0x00 0x05 0x00 0x4130b0 0x1bc 0x4c4 0x00 0x05 0x00 0x4130b0 0x1c0 0x4c8 0x00 0x05 0x00 0x4130b0 0x1c4 0x4cc 0x00 0x05 0x00 0x4130b0 0x1c8 0x4d0 0x00 0x05 0x00 0x4130b0 0x1cc 0x4d4 0x00 0x05 0x00 0x4130b0 0x1d0 0x4d8 0x00 0x05 0x00 0x4130b0 0x1d4 0x4dc 0x00 0x05 0x00 0x4130b0 0x1d8 0x4e0 0x00 0x05 0x00 0x4130b0 0x1dc 0x4e4 0x00 0x05 0x00 0x4130b0 0x1e4 0x4ec 0x00 0x05 0x00 0x4130b0 0x1e8 0x4f0 0x00 0x05 0x00 0x4130b0 0x1ec 0x4f4 0x00 0x05 0x00 0x4130b0 0x1f0 0x4f8 0x00 0x05 0x00 0x4130b0 0x58 0x2b0 0x00 0x05 0x00 0x4130b0 0x50 0x2a8 0x00 0x05 0x00 0x4130b0 0x54 0x2ac 0x00 0x05 0x00 0x4130b0 0x64 0x2bc 0x00 0x05 0x00 0x4130b0 0x60 0x2b8 0x00 0x05 0x00 0x4130b0 0x4c 0x2a4 0x00 0x05 0x00 0x4130b0 0x80 0x370 0x00 0x05 0x00 0x4130b0 0x7c 0x36c 0x00 0x05 0x00 0x4130b0 0x78 0x368 0x00 0x05 0x00 0x4130b0 0x84 0x374 0x00 0x05 0x00 0x4130b0 0x144 0x434 0x00 0x05 0x00 0x4130b0 0x138 0x428 0x00 0x05 0x00 0x4130b0 0x128 0x418 0x00 0x05 0x00 0x4130b0 0x140 0x430 0x00 0x05 0x00 0x4130b0 0x14c 0x43c 0x00 0x05 0x00 0x4130b0 0x12c 0x41c 0x00 0x05 0x00 0x4130b0 0x148 0x438 0x00 0x05 0x00 0x4130b0 0x134 0x424 0x00 0x05 0x00 0x4130b0 0x280 0x588 0x00 0x05 0x00 0x4130b0 0x284 0x58c 0x00 0x05 0x00 0x4130b0 0x288 0x590 0x00 0x05 0x00 0x4130b0 0x28c 0x594 0x00 0x05 0x00 0x4130b0 0x290 0x598 0x00 0x05 0x00 0x4130b0 0x294 0x59c 0x00 0x05 0x00 0x4130b0 0x1a8 0x4b0 0x00 0x05 0x00 0x4130b0 0x170 0x478 0x00 0x05 0x00 0x4130b0 0x174 0x47c 0x00 0x05 0x00 0x4130b0 0x178 0x480 0x00 0x05 0x00 0x4130b0 0x180 0x488 0x00 0x05 0x00 0x4130b0 0x184 0x48c 0x00 0x05 0x00 0x4130b0 0x188 0x490 0x00 0x05 0x00 0x4130b0 0x220 0x528 0x00 0x05 0x00 0x4130b0 0x154 0x444 0x00 0x05 0x00 0x4130b0 0x158 0x448 0x00 0x05 0x00 0x4130b0 0x224 0x52c 0x00 0x05 0x00 0x4130b0 0x228 0x530 0x00 0x05 0x00 0x4130b0 0x244 0x54c 0x814 0x04 0x04 0x1b0b1 0x248 0x550 0x00 0x04 0x00 0x1b0b1>;
						linux,phandle = <0x10>;
						phandle = <0x10>;
					};

					hoggrp_sleep {
						fsl,pins = <0x2a0 0x5a8 0x00 0x00 0x00 0x4128b0 0x130 0x420 0x00 0x05 0x00 0x4100b0 0x150 0x440 0x00 0x05 0x00 0x4100b0 0x248 0x550 0x00 0x05 0x00 0x4130b0 0x244 0x54c 0x00 0x05 0x00 0x4130b0>;
						linux,phandle = <0x11>;
						phandle = <0x11>;
					};
				};

				uart3 {

					uart3grp-1 {
						fsl,pins = <0x8c 0x37c 0x00 0x02 0x00 0x41b0b1 0x88 0x378 0x808 0x02 0x02 0x41b0b1 0x120 0x410 0x80c 0x02 0x04 0x41b0b1 0x124 0x414 0x00 0x02 0x00 0x4130b1>;
						linux,phandle = <0x09>;
						phandle = <0x09>;
					};
				};
			};

			csi@020e4000 {
				compatible = "fsl,imx6sl-csi";
				reg = <0x20e4000 0x4000>;
				interrupts = <0x00 0x07 0x04>;
				clocks = <0x02 0x00 0x02 0x00 0x02 0x00>;
				clock-names = "disp-axi\0csi_mclk\0dcic";
				status = "disabled";
			};

			spdc@020e8000 {
				reg = <0x20e8000 0x4000>;
				interrupts = <0x00 0x06 0x04>;
			};

			sdma@020ec000 {
				compatible = "fsl,imx6sl-sdma\0fsl,imx35-sdma";
				reg = <0x20ec000 0x4000>;
				interrupts = <0x00 0x02 0x04>;
				clocks = <0x02 0x79 0x02 0x79>;
				clock-names = "ipg\0ahb";
				#dma-cells = <0x03>;
				iram = <0x12>;
				fsl,sdma-ram-script-name = "imx/sdma/sdma-imx6q.bin";
				linux,phandle = <0x07>;
				phandle = <0x07>;
			};

			pxp@020f0000 {
				compatible = "fsl,imx6sl-pxp-dma\0fsl,imx6dl-pxp-dma";
				reg = <0x20f0000 0x4000>;
				interrupts = <0x00 0x62 0x04>;
				clocks = <0x02 0x6f 0x02 0x00>;
				clock-names = "pxp-axi\0disp-axi";
				status = "okay";
			};

			epdc@020f4000 {
				compatible = "fsl,imx6sl-epdc\0fsl,imx6dl-epdc";
				reg = <0x20f4000 0x4000>;
				interrupts = <0x00 0x61 0x04>;
				clocks = <0x02 0x70 0x02 0x73>;
				clock-names = "epdc_axi\0epdc_pix";
				pinctrl-names = "default";
				pinctrl-0 = <0x13>;
				status = "okay";
			};

			dcp@020fc000 {
				reg = <0x20fc000 0x4000>;
				interrupts = <0x00 0x63 0x04>;
			};
		};

		aips-bus@02100000 {
			compatible = "fsl,aips-bus\0simple-bus";
			#address-cells = <0x01>;
			#size-cells = <0x01>;
			reg = <0x2100000 0x100000>;
			ranges;

			usb@02184000 {
				compatible = "fsl,imx6sl-usb\0fsl,imx27-usb";
				reg = <0x2184000 0x200>;
				interrupts = <0x00 0x2b 0x04>;
				clocks = <0x02 0x80>;
				fsl,usbphy = <0x14>;
				fsl,usbmisc = <0x15 0x00>;
				fsl,anatop = <0x0c>;
				status = "okay";
				vbus-supply = <0x16>;
				pinctrl-names = "default";
				pinctrl-0 = <0x17>;
				disable-over-current;
				imx6-usb-charger-detection;
			};

			usb@02184200 {
				compatible = "fsl,imx6sl-usb\0fsl,imx27-usb";
				reg = <0x2184200 0x200>;
				interrupts = <0x00 0x2a 0x04>;
				clocks = <0x02 0x80>;
				fsl,usbphy = <0x18>;
				fsl,usbmisc = <0x15 0x01>;
				status = "disabled";
			};

			usb@02184400 {
				compatible = "fsl,imx6sl-usb\0fsl,imx27-usb";
				reg = <0x2184400 0x200>;
				interrupts = <0x00 0x28 0x04>;
				clocks = <0x02 0x80>;
				fsl,usbmisc = <0x15 0x02>;
				phy_type = "hsic";
				fsl,usbphy = <0x19>;
				fsl,anatop = <0x0c>;
				status = "disabled";
			};

			usbmisc@02184800 {
				#index-cells = <0x01>;
				compatible = "fsl,imx6sl-usbmisc\0fsl,imx6q-usbmisc";
				reg = <0x2184800 0x200>;
				clocks = <0x02 0x80>;
				vbus-wakeup-supply = <0x1a>;
				linux,phandle = <0x15>;
				phandle = <0x15>;
			};

			usdhc@02190000 {
				compatible = "fsl,imx6sl-usdhc\0fsl,imx6q-usdhc";
				reg = <0x2190000 0x4000>;
				interrupts = <0x00 0x16 0x04>;
				clocks = <0x02 0x81 0x02 0x81 0x02 0x81>;
				clock-names = "ipg\0ahb\0per";
				bus-width = <0x04>;
				status = "okay";
				pinctrl-names = "default\0state_100mhz\0state_200mhz";
				pinctrl-0 = <0x1b>;
				pinctrl-1 = <0x1c>;
				pinctrl-2 = <0x1d>;
				keep-power-in-suspend;
				non-removable;
				fsl,delay-line;
			};

			usdhc@02194000 {
				compatible = "fsl,imx6sl-usdhc\0fsl,imx6q-usdhc";
				reg = <0x2194000 0x4000>;
				interrupts = <0x00 0x17 0x04>;
				clocks = <0x02 0x82 0x02 0x82 0x02 0x82>;
				clock-names = "ipg\0ahb\0per";
				bus-width = <0x08>;
				status = "okay";
				pinctrl-names = "default\0state_100mhz\0state_200mhz";
				pinctrl-0 = <0x1e>;
				pinctrl-1 = <0x1f>;
				pinctrl-2 = <0x20>;
				non-removable;
				keep-power-in-suspend;
				fsl,delay-line;
				fsl,sig-voltage-switch-disable;
				fsl,sdr104-support-override;
				fsl,ddr50-support-override;
				fsl,sdr50-support-override;
			};

			usdhc@02198000 {
				compatible = "fsl,imx6sl-usdhc\0fsl,imx6q-usdhc";
				reg = <0x2198000 0x4000>;
				interrupts = <0x00 0x18 0x04>;
				clocks = <0x02 0x83 0x02 0x83 0x02 0x83>;
				clock-names = "ipg\0ahb\0per";
				bus-width = <0x04>;
				status = "disabled";
			};

			usdhc@0219c000 {
				compatible = "fsl,imx6sl-usdhc\0fsl,imx6q-usdhc";
				reg = <0x219c000 0x4000>;
				interrupts = <0x00 0x19 0x04>;
				clocks = <0x02 0x84 0x02 0x84 0x02 0x84>;
				clock-names = "ipg\0ahb\0per";
				bus-width = <0x04>;
				status = "disabled";
			};

			i2c@021a0000 {
				#address-cells = <0x01>;
				#size-cells = <0x00>;
				compatible = "fsl,imx6sl-i2c\0fsl,imx21-i2c";
				reg = <0x21a0000 0x4000>;
				interrupts = <0x00 0x24 0x04>;
				clocks = <0x02 0x6a>;
				status = "okay";
				clock-frequency = <0x5b8d8>;
				pinctrl-names = "default";
				pinctrl-0 = <0x21>;

				bd7181x@4b {
					reg = <0x4b>;
					compatible = "rohm,bd71815";
					gpio_intr = <0x22 0x14 0x01>;

					gpo {
						rohm,mode = <0x03>;
					};

					regulators {
						#address-cells = <0x01>;
						#size-cells = <0x00>;

						regulator@0 {
							reg = <0x00>;
							regulator-compatible = "buck1";
							regulator-min-microvolt = "\0\f5";
							regulator-max-microvolt = <0x1e8480>;
							regulator-boot-on;
							regulator-always-on;
							regulator-ramp-delay = <0x186a>;
							linux,phandle = <0x05>;
							phandle = <0x05>;
						};

						regulator@1 {
							reg = <0x01>;
							regulator-compatible = "buck2";
							regulator-min-microvolt = "\0\f5";
							regulator-max-microvolt = <0x1e8480>;
							regulator-boot-on;
							regulator-always-on;
							regulator-ramp-delay = <0x186a>;
							linux,phandle = <0x03>;
							phandle = <0x03>;
						};

						regulator@2 {
							reg = <0x02>;
							regulator-compatible = "buck3";
							regulator-min-microvolt = <0x124f80>;
							regulator-max-microvolt = <0x2932e0>;
							regulator-boot-on;
							regulator-always-on;
						};

						regulator@3 {
							reg = <0x03>;
							regulator-compatible = "buck4";
							regulator-min-microvolt = <0x10c8e0>;
							regulator-max-microvolt = <0x1c3a90>;
							regulator-always-on;
						};

						regulator@4 {
							reg = <0x04>;
							regulator-compatible = "buck5";
							regulator-min-microvolt = <0x1b7740>;
							regulator-max-microvolt = <0x325aa0>;
							regulator-always-on;
						};

						regulator@5 {
							reg = <0x05>;
							regulator-compatible = "ldo1";
							regulator-min-microvolt = "\0\f5";
							regulator-max-microvolt = <0x325aa0>;
							regulator-always-on;
						};

						regulator@6 {
							reg = <0x06>;
							regulator-compatible = "ldo2";
							regulator-min-microvolt = "\0\f5";
							regulator-max-microvolt = <0x325aa0>;
							regulator-always-on;
						};

						regulator@7 {
							reg = <0x07>;
							regulator-compatible = "ldo3";
							regulator-name = "ldo3";
							regulator-min-microvolt = <0x2dc6c0>;
							regulator-max-microvolt = <0x2dc6c0>;
							regulator-always-on;
							linux,phandle = <0x16>;
							phandle = <0x16>;
						};

						regulator@8 {
							reg = <0x08>;
							regulator-compatible = "ldo4";
							regulator-min-microvolt = "\0\f5";
							regulator-max-microvolt = <0x325aa0>;
						};

						regulator@9 {
							reg = <0x09>;
							regulator-compatible = "ldo5";
							regulator-name = "ldo5";
							regulator-min-microvolt = "\0\f5";
							regulator-max-microvolt = <0x325aa0>;
						};

						regulator@10 {
							reg = <0x0a>;
							regulator-compatible = "dvref";
							regulator-always-on;
						};

						regulator@11 {
							reg = <0x0b>;
							regulator-compatible = "lpsr";
						};

						regulator@12 {
							reg = <0x0c>;
							regulator-compatible = "wled";
							regulator-min-microamp = <0x0a>;
							regulator-max-microamp = <0x61a8>;
						};
					};
				};

				fp9928@48 {
					compatible = "fp9928";
					reg = <0x48>;
				};
			};

			i2c@021a4000 {
				#address-cells = <0x01>;
				#size-cells = <0x00>;
				compatible = "fsl,imx6sl-i2c\0fsl,imx21-i2c";
				reg = <0x21a4000 0x4000>;
				interrupts = <0x00 0x25 0x04>;
				clocks = <0x02 0x6b>;
				status = "okay";
				clock-frequency = <0x5b8d8>;
				pinctrl-names = "default";
				pinctrl-0 = <0x23>;

				zforce2@50 {
					compatible = "zforce2";
					reg = <0x50>;
				};
			};

			i2c@021a8000 {
				#address-cells = <0x01>;
				#size-cells = <0x00>;
				compatible = "fsl,imx6sl-i2c\0fsl,imx21-i2c";
				reg = <0x21a8000 0x4000>;
				interrupts = <0x00 0x26 0x04>;
				clocks = <0x02 0x6c>;
				status = "okay";
				clock-frequency = <0x5b8d8>;
				pinctrl-names = "default";
				pinctrl-0 = <0x24>;
			};

			mmdc@021b0000 {
				compatible = "fsl,imx6sl-mmdc\0fsl,imx6q-mmdc";
				reg = <0x21b0000 0x4000>;
			};

			rng@021b4000 {
				compatible = "fsl,imx6sl-rng\0fsl,imx-rng\0imx-rng";
				reg = <0x21b4000 0x4000>;
				interrupts = <0x00 0x05 0x04>;
				clocks = <0x02 0x00>;
			};

			weim@021b8000 {
				reg = <0x21b8000 0x4000>;
				interrupts = <0x00 0x0e 0x04>;
			};

			ocotp-ctrl@021bc000 {
				compatible = "syscon";
				reg = <0x21bc000 0x4000>;
				clocks = <0x02 0x6d>;
				linux,phandle = <0x0d>;
				phandle = <0x0d>;
			};

			ocotp-fuse@021bc000 {
				compatible = "fsl,imx6sl-ocotp\0fsl,imx6q-ocotp";
				reg = <0x21bc000 0x4000>;
				clocks = <0x02 0x6d>;
			};

			audmux@021d8000 {
				compatible = "fsl,imx6sl-audmux\0fsl,imx31-audmux";
				reg = <0x21d8000 0x4000>;
				status = "disabled";
			};
		};

		ramoops_device {
			compatible = "fsl,mxc_ramoops";
			record_size = <0x80000>;
			console_size = <0x40000>;
			ftrace_size = <0x40000>;
			dump_oops = <0x01>;
			status = "okay";
		};
	};

	wifi_brcm {
		compatible = "bcm,bcm43430";
		wl_reg_on = <0x25 0x0f 0x00>;
		wl_host_wake = <0x26 0x1f 0x00>;
	};

	bt_pwr_ctrl {
		compatible = "amzn,bt_pwr_ctrl";
		bt_rst = <0x25 0x13 0x00>;
		bt_dev_wake = <0x27 0x0a 0x00>;
		bt_host_wake = <0x26 0x1d 0x00>;
	};

	heisenberg_hall {
		compatible = "amzn,heisenberg_hall";
		hall_int_n = <0x22 0x10 0x00>;
		status = "okay";
	};

	regulator-virtuals {
		compatible = "simple-bus";

		virt-buck1 {
			compatible = "regulator-virtual";
			virtual-supply = "buck1";
		};

		virt-buck2 {
			compatible = "regulator-virtual";
			virtual-supply = "buck2";
		};

		virt-buck3 {
			compatible = "regulator-virtual";
			virtual-supply = "buck3";
		};

		virt-buck4 {
			compatible = "regulator-virtual";
			virtual-supply = "buck4";
		};

		virt-buck5 {
			compatible = "regulator-virtual";
			virtual-supply = "buck5";
		};

		virt-ldo1 {
			compatible = "regulator-virtual";
			virtual-supply = "ldo1";
		};

		virt-ldo2 {
			compatible = "regulator-virtual";
			virtual-supply = "ldo2";
		};

		virt-ldo3 {
			compatible = "regulator-virtual";
			virtual-supply = "ldo3";
		};

		virt-ldo4 {
			compatible = "regulator-virtual";
			virtual-supply = "ldo4";
		};

		virt-ldo5 {
			compatible = "regulator-virtual";
			virtual-supply = "ldo5";
		};

		user-dvref {
			compatible = "userspace_consumer";
			uc-name = "dvref";
			suck-supply = "dvref";
		};

		user-lpsr {
			compatible = "userspace_consumer";
			uc-name = "lpsr";
			suck-supply = "lpsr";
		};

		virt-wled {
			compatible = "regulator-virtual";
			virtual-supply = "wled";
		};
	};
};
